# PIC32CK2051SG01100 device description
Architecture: CORTEX-M33; Family: PIC32CK; Series: PIC32CKSG01
Registers are 32-bit, read-write, reset 0x0 unless marked. A register's access mark holds for its fields unless they carry their own. Offsets are from the block's base; [hi:lo] are bit positions; lines under a group give offsets from that group; {n}, {i} and the like mark numbered series; 'fields as' and 'values as' point back to an identical list.

## HMATRIX2 — HSB Matrix
Instances: HMATRIX 0x44806000
{0x0+4i} MCFG[{i}] (i=0..15) reset 0x2 — Master Configuration
  [2:0] ULBT — Undefined Length Burst Type
    0=INFINITE (Infinite Length); 1=SINGLE (Single Access); 2=FOUR_BEAT (Four Beat Burst); 3=EIGHT_BEAT (Eight Beat Burst); 4=SIXTEEN_BEAT (Sixteen Beat Burst)
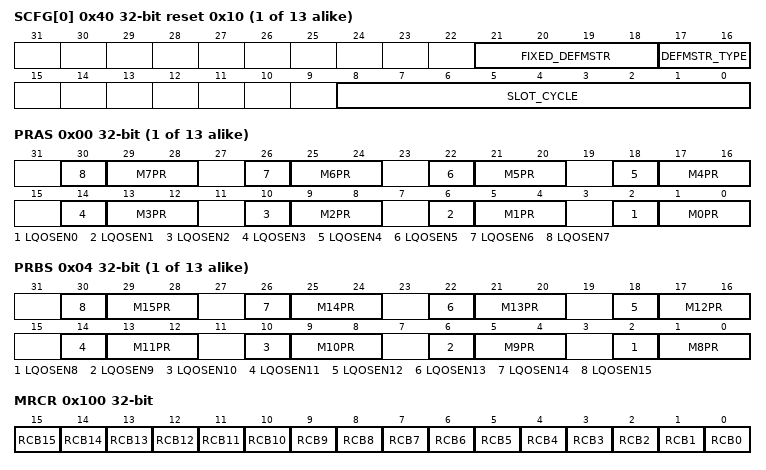
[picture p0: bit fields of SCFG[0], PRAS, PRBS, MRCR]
{0x40+4i} SCFG[{i}] (i=0..12) reset 0x10 — Slave Configuration
  [21:18] FIXED_DEFMSTR — Fixed Index of Default Master
  [17:16] DEFMSTR_TYPE — Default Master Type
    0=NO_DEFAULT (No Default Master. At the end of current slave access, if no other master request is pending, the slave is deconnected from all masters. This resusts in having a one cycle latency for the first transfer of a burst.); 1=LAST_DEFAULT (Last Default Master At the end of current slave access, if no other master request is pending, the slave stay connected with the last master havingaccessed it.This resusts in not having the one cycle latency when the last master re-trying access on the slave.); 2=FIXED_DEFAULT (Fixed Default Master At the end of current slave access, if no other master request is pending, the slave connects with fixed master which numberis in FIXED_DEFMSTR register.This resusts in not having the one cycle latency when the fixed master re-trying access on the slave.)
  [8:0] SLOT_CYCLE — Maximum Number of Allowed Cycles for a Burst
{0x80+8i} PRS[{i}] (i=0..12) group
  0x00 PRAS — Priority A for Slave
    [4n+2] LQOSEN{n} (n=0..7) — Latency Quality Of Service Enable for Master {n}
    [4n+1:4n] M{n}PR (n=0..7) — Master {n} Priority
  0x04 PRBS — Priority B for Slave
    [4n-30] LQOSEN{n} (n=8..15) — Latency Quality Of Service Enable for Master {n}
    [4n-31:4n-32] M{n}PR (n=8..15) — Master {n} Priority
0x100 MRCR — Master Remap Control
  [all] fields
    0=DIS (Disable remapped address decoding for master); 1=ENA (Enable remapped address decoding for master)
  [n] RCB{n} (n=0..15) — Remap Command Bit for Master {n}
{0x110+4i} SFR[{i}] (i=0..12) — Special Function
  [31:0] SFR — Special Function Register
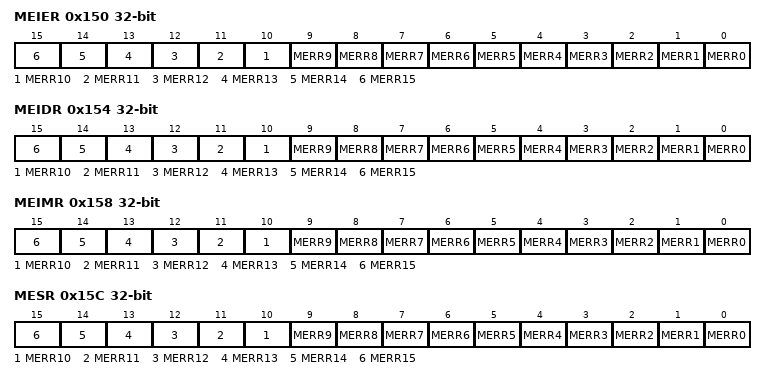
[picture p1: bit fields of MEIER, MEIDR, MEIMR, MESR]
0x150 MEIER wo reset not defined (atomic set of MEIMR) — Master Error Interrupt Enable
  [n] MERR{n} (n=0..15) — Master {n} Access Error
0x154 MEIDR wo reset not defined (atomic clear of MEIMR) — Master Error Interrupt Disable
  [n] MERR{n} (n=0..15) — Master {n} Access Error
0x158 MEIMR ro reset not defined — Master Error Interrupt Mask
  [n] MERR{n} (n=0..15) — Master {n} Access Error
0x15C MESR ro reset not defined (atomic clear) — Master Error Status
  [n] MERR{n} (n=0..15) — Master {n} Access Error
{0x160+4i} MEAR[{i}] (i=0..15) ro reset not defined — Master Error Address

## HSM — Hardware Security Module
Instances: HSM 0x48000000
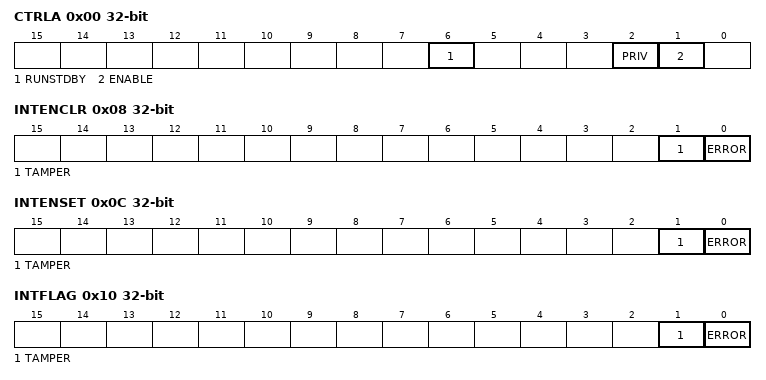
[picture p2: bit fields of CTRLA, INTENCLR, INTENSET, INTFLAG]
0x00 CTRLA — CONTROL REGISTER A
  [6] RUNSTDBY — Run In Standby bit
  [2] PRIV — Privileged Access Only bit
  [1] ENABLE — Clock Enable bit
0x04 CTRLB — CONTROL REGISTER B
  [0] CANCEL — Cancel Command
0x08 INTENCLR (atomic clear) — INTERRUPT ENABLE CLEAR REGISTER
  [1] TAMPER — Tamper Interrupt Enable
  [0] ERROR — Error Interrupt Enable
0x0C INTENSET (atomic set) — INTERRUPT ENABLE SET
  fields as INTENCLR
0x10 INTFLAG (atomic clear) — INTERRUPT FLAG
  [1] TAMPER — Tamper Interrupt Flag
  [0] ERROR — Error Interrupt Flag
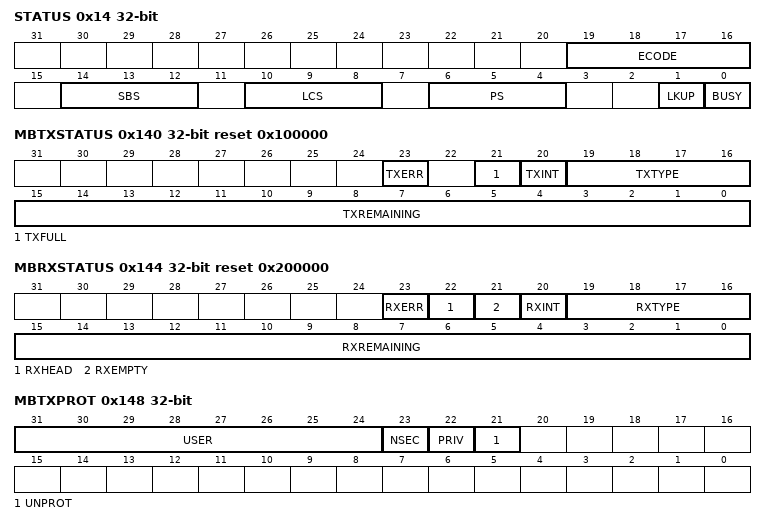
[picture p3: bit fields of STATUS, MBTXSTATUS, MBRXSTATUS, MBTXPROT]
0x14 STATUS
  [19:16] ECODE — ERROR CODE
  [14:12] SBS — SECURE BOOT STATE
  [10:8] LCS — LIFECYCLE STATE
  [6:4] PS — PROCESSING STATE
  [1] LKUP — HSM CPU LOCKUP
  [0] BUSY — HSM CPU BUSY
{0x100+4i} MBFIFO[{i}] (i=0..15) — MAILBOX FIFO
0x140 MBTXSTATUS reset 0x100000 — MAILBOX TRANSMIT STATUS
  [23] TXERR — TRANSMIT ERROR
  [21] TXFULL — TRANSMIT FIFO FULL
  [20] TXINT — TRANSMIT FIFO INTERRUPT FLAG
  [19:16] TXTYPE — TRANSMIT MESSAGE HEADER TYPE
  [15:0] TXREMAINING — TRANSMIT BYTES REMAINING
0x144 MBRXSTATUS reset 0x200000 — MAILBOX RECEIVE STATUS
  [23] RXERR — RECEIVE ERROR
  [22] RXHEAD — Receive Header Next Word bit
  [21] RXEMPTY — RECEIVE FIFO FULL
  [20] RXINT — RECEIVE FIFO INTERRUPT FLAG
  [19:16] RXTYPE — RECEIVE MESSAGE HEADER TYPE
  [15:0] RXREMAINING — RECEIVE BYTES REMAINING
0x148 MBTXPROT — MAILBOX TX PROTECTION
  [31:24] USER — USER SIDEBAND
  [23] NSEC — MAILBOX MESSAGE NON-SECURE ACCESS
  [22] PRIV — MAILBOX MESSAGE PRIVILEDGED ACCESS
  [21] UNPROT — MAILBOX UNPROTECTED
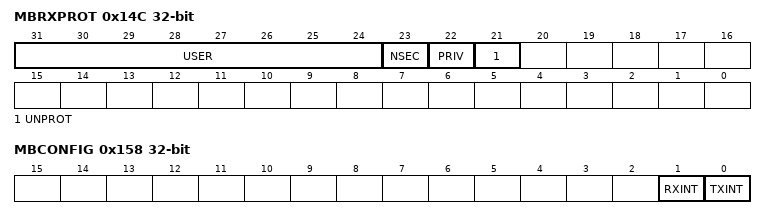
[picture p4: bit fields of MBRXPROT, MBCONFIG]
0x14C MBRXPROT — MAILBOX RX PROTECTION
  fields as MBTXPROT
0x150 MBTXHEAD — MAILBOX TRANSMIT HEADER
  [31:0] TXHEAD — MAILBOX TRANSMIT HEADER REGISTER
0x154 MBRXHEAD — MAILBOX RECEIVE HEADER
  [31:0] RXHEAD — MAILBOX RECEIVE HEADER REGISTER
0x158 MBCONFIG — MAILBOX CONFIGURATION
  [1] RXINT — MAILBOX RECEIVE INTERRUPT ENABLE
  [0] TXINT — MAILBOX TRANSMIT INTERRUPT ENABLE
